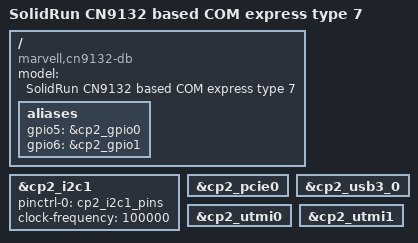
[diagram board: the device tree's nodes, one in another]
/*
 * Copyright (C) 2020 SolidRun ltd.
 *
 * SPDX-License-Identifier:    GPL-2.0
 * https://spdx.org/licenses
 */

/* Device Tree file for the SolidRun cn1932 based com express type 7, cp0  */

#undef CP110_NAME
#undef CP110_NUM
#undef CP110_PCIE_MEM_SIZE
#undef CP110_PCIEx_CPU_MEM_BASE
#undef CP110_PCIEx_BUS_MEM_BASE

/* CP110-2 Settings */
#define CP110_NAME			cp2
#define CP110_NUM			2
#define CP110_PCIE_MEM_SIZE(iface)	(0xf00000)
#define CP110_PCIEx_CPU_MEM_BASE(iface)	(0xe5000000 + (iface) *  0x1000000)
#define CP110_PCIEx_BUS_MEM_BASE(iface)	(CP110_PCIEx_CPU_MEM_BASE(iface))

#include "armada-cp110.dtsi"

/ {
	model = "SolidRun CN9132 based COM express type 7";
	compatible = "marvell,cn9132-db";

	aliases {
		gpio5 = &cp2_gpio0;
		gpio6 = &cp2_gpio1;
		// fuse7 = &cp2_ld_efuse0;	/* bank 70 RO */
		// fuse8 = &cp2_ld_efuse1;	/* bank 71 RW */
	};

};

&cp2_i2c1 {
        pinctrl-names = "default";
        pinctrl-0 = <&cp2_i2c1_pins>;
        status = "okay";
        clock-frequency = <100000>;
};


&cp2_pcie0 {
		/* non-prefetchable memory */
	ranges =<0x82000000 0 0xe5000000 0 0xe5000000 0 0x1000000>;
};

&cp2_usb3_0 {
	status = "okay";
};

&cp2_utmi0 {
	status = "okay";
};

&cp2_utmi1 {
	status = "okay";
};
